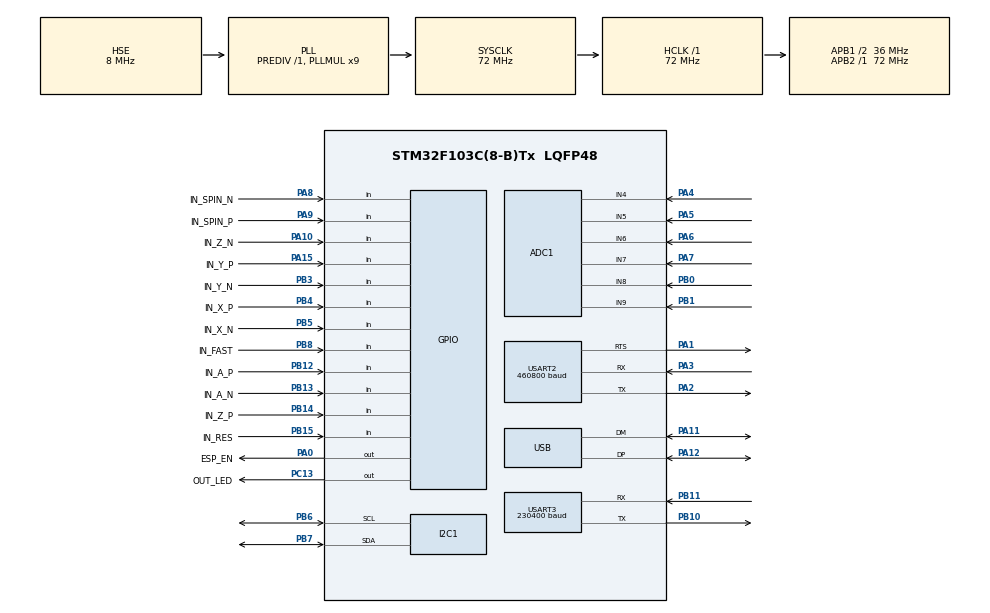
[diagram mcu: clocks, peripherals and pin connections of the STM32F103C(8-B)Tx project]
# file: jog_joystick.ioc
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ADC1.Channel-1\#ChannelRegularConversion=ADC_CHANNEL_4
ADC1.Channel-2\#ChannelRegularConversion=ADC_CHANNEL_5
ADC1.Channel-3\#ChannelRegularConversion=ADC_CHANNEL_6
ADC1.Channel-4\#ChannelRegularConversion=ADC_CHANNEL_7
ADC1.Channel-5\#ChannelRegularConversion=ADC_CHANNEL_8
ADC1.Channel-6\#ChannelRegularConversion=ADC_CHANNEL_9
ADC1.Channel-7\#ChannelRegularConversion=ADC_CHANNEL_VREFINT
ADC1.Channel-8\#ChannelRegularConversion=ADC_CHANNEL_VREFINT
ADC1.ContinuousConvMode=DISABLE
ADC1.ExternalTrigConv=ADC_EXTERNALTRIGCONV_T3_TRGO
ADC1.NbrOfConversion=8
ADC1.NbrOfConversionFlag=1
ADC1.Rank-1\#ChannelRegularConversion=1
ADC1.Rank-2\#ChannelRegularConversion=2
ADC1.Rank-3\#ChannelRegularConversion=3
ADC1.Rank-4\#ChannelRegularConversion=4
ADC1.Rank-5\#ChannelRegularConversion=5
ADC1.Rank-6\#ChannelRegularConversion=6
ADC1.Rank-7\#ChannelRegularConversion=7
ADC1.Rank-8\#ChannelRegularConversion=8
ADC1.SamplingTime-1\#ChannelRegularConversion=ADC_SAMPLETIME_239CYCLES_5
ADC1.SamplingTime-2\#ChannelRegularConversion=ADC_SAMPLETIME_239CYCLES_5
ADC1.SamplingTime-3\#ChannelRegularConversion=ADC_SAMPLETIME_239CYCLES_5
ADC1.SamplingTime-4\#ChannelRegularConversion=ADC_SAMPLETIME_239CYCLES_5
ADC1.SamplingTime-5\#ChannelRegularConversion=ADC_SAMPLETIME_239CYCLES_5
ADC1.SamplingTime-6\#ChannelRegularConversion=ADC_SAMPLETIME_239CYCLES_5
ADC1.SamplingTime-7\#ChannelRegularConversion=ADC_SAMPLETIME_239CYCLES_5
ADC1.SamplingTime-8\#ChannelRegularConversion=ADC_SAMPLETIME_1CYCLE_5
ADC1.master=1
Dma.ADC1.0.Direction=DMA_PERIPH_TO_MEMORY
Dma.ADC1.0.Instance=DMA1_Channel1
Dma.ADC1.0.MemDataAlignment=DMA_MDATAALIGN_HALFWORD
Dma.ADC1.0.MemInc=DMA_MINC_ENABLE
Dma.ADC1.0.Mode=DMA_CIRCULAR
Dma.ADC1.0.PeriphDataAlignment=DMA_PDATAALIGN_HALFWORD
Dma.ADC1.0.PeriphInc=DMA_PINC_DISABLE
Dma.ADC1.0.Priority=DMA_PRIORITY_MEDIUM
Dma.Request0=ADC1
FREERTOS.INCLUDE_pcTaskGetTaskName=0
FREERTOS.INCLUDE_uxTaskGetStackHighWaterMark=0
FREERTOS.INCLUDE_uxTaskPriorityGet=0
FREERTOS.INCLUDE_vTaskDelayUntil=1
FREERTOS.INCLUDE_vTaskDelete=0
FREERTOS.INCLUDE_vTaskPrioritySet=0
FREERTOS.INCLUDE_vTaskSuspend=0
FREERTOS.INCLUDE_xEventGroupSetBitFromISR=0
FREERTOS.INCLUDE_xTaskGetCurrentTaskHandle=0
FREERTOS.INCLUDE_xTaskGetHandle=0
FREERTOS.INCLUDE_xTaskGetSchedulerState=0
FREERTOS.INCLUDE_xTimerPendFunctionCall=0
FREERTOS.MEMORY_ALLOCATION=1
FREERTOS.Tasks01=defaultTask,-1,256,StartDefaultTask,As weak,NULL,Static,defaultTaskBuffer,defaultTaskControlBlock
FREERTOS.configCHECK_FOR_STACK_OVERFLOW=0
FREERTOS.configENABLE_BACKWARD_COMPATIBILITY=0
FREERTOS.configMAX_PRIORITIES=4
FREERTOS.configMINIMAL_STACK_SIZE=128
FREERTOS.configTIMER_QUEUE_LENGTH=8
FREERTOS.configTIMER_TASK_STACK_DEPTH=128
FREERTOS.configTOTAL_HEAP_SIZE=1024
FREERTOS.configUSE_APPLICATION_TASK_TAG=1
FREERTOS.configUSE_NEWLIB_REENTRANT=1
FREERTOS.configUSE_TRACE_FACILITY=0
I2C1.I2C_Mode=I2C_Standard
IWDG.Prescaler=IWDG_PRESCALER_8
Mcu.Family=STM32F1
Mcu.Name=STM32F103C(8-B)Tx
Mcu.Package=LQFP48
NVIC.DMA1_Channel1_IRQn=true\:5\:0\:false\:false\:true\:true\:false\:true\:true
NVIC.I2C1_ER_IRQn=true\:5\:0\:false\:false\:true\:true\:true\:true\:true
NVIC.I2C1_EV_IRQn=true\:5\:0\:false\:false\:true\:true\:true\:true\:true
NVIC.PriorityGroup=NVIC_PRIORITYGROUP_4
NVIC.TIM4_IRQn=true\:15\:0\:false\:false\:true\:false\:false\:true\:true
NVIC.TimeBase=TIM4_IRQn
NVIC.TimeBaseIP=TIM4
NVIC.USART2_IRQn=true\:5\:0\:false\:false\:true\:true\:true\:true\:true
NVIC.USART3_IRQn=true\:5\:0\:false\:false\:true\:true\:true\:true\:true
NVIC.USB_LP_CAN1_RX0_IRQn=true\:5\:0\:false\:false\:true\:true\:false\:true\:true
PA0-WKUP.GPIO_Label=ESP_EN
PA0-WKUP.GPIO_ModeDefaultOutputPP=GPIO_MODE_OUTPUT_OD
PA0-WKUP.GPIO_PuPd=GPIO_NOPULL
PA0-WKUP.Signal=GPIO_Output
PA1.Mode=RTS_Only
PA1.Signal=USART2_RTS
PA10.GPIO_Label=IN_Z_N
PA10.Signal=GPIO_Input
PA11.Mode=Device
PA11.Signal=USB_DM
PA12.Mode=Device
PA12.Signal=USB_DP
PA13.Mode=Serial_Wire
PA13.Signal=SYS_JTMS-SWDIO
PA14.Mode=Serial_Wire
PA14.Signal=SYS_JTCK-SWCLK
PA15.GPIO_Label=IN_Y_P
PA15.Signal=GPIO_Input
PA2.Mode=Asynchronous
PA2.Signal=USART2_TX
PA3.Mode=Asynchronous
PA3.Signal=USART2_RX
PA4.Signal=ADCx_IN4
PA5.Signal=ADCx_IN5
PA6.Signal=ADCx_IN6
PA7.Signal=ADCx_IN7
PA8.GPIO_Label=IN_SPIN_N
PA8.Signal=GPIO_Input
PA9.GPIO_Label=IN_SPIN_P
PA9.Signal=GPIO_Input
PB0.Signal=ADCx_IN8
PB1.Signal=ADCx_IN9
PB10.Mode=Asynchronous
PB10.Signal=USART3_TX
PB11.Mode=Asynchronous
PB11.Signal=USART3_RX
PB12.GPIO_Label=IN_A_P
PB12.Signal=GPIO_Input
PB13.GPIO_Label=IN_A_N
PB13.Signal=GPIO_Input
PB14.GPIO_Label=IN_Z_P
PB14.Signal=GPIO_Input
PB15.GPIO_Label=IN_RES
PB15.Signal=GPIO_Input
PB3.GPIO_Label=IN_Y_N
PB3.Signal=GPIO_Input
PB4.GPIO_Label=IN_X_P
PB4.Signal=GPIO_Input
PB5.GPIO_Label=IN_X_N
PB5.Signal=GPIO_Input
PB6.Mode=I2C
PB6.Signal=I2C1_SCL
PB7.Mode=I2C
PB7.Signal=I2C1_SDA
PB8.GPIO_Label=IN_FAST
PB8.Signal=GPIO_Input
PC13-TAMPER-RTC.GPIO_Label=OUT_LED
PC13-TAMPER-RTC.GPIO_ModeDefaultOutputPP=GPIO_MODE_OUTPUT_OD
PC13-TAMPER-RTC.GPIO_PuPd=GPIO_NOPULL
PC13-TAMPER-RTC.PinState=GPIO_PIN_SET
PC13-TAMPER-RTC.Signal=GPIO_Output
PC14-OSC32_IN.Mode=LSE-External-Oscillator
PC14-OSC32_IN.Signal=RCC_OSC32_IN
PC15-OSC32_OUT.Mode=LSE-External-Oscillator
PC15-OSC32_OUT.Signal=RCC_OSC32_OUT
PD0-OSC_IN.Mode=HSE-External-Oscillator
PD0-OSC_IN.Signal=RCC_OSC_IN
PD1-OSC_OUT.Mode=HSE-External-Oscillator
PD1-OSC_OUT.Signal=RCC_OSC_OUT
ProjectManager.HeapSize=0x200
ProjectManager.StackSize=0x400
ProjectManager.TargetToolchain=Makefile
RCC.ADCPresc=RCC_ADCPCLK2_DIV6
RCC.AHBFreq_Value=72000000
RCC.APB1CLKDivider=RCC_HCLK_DIV2
RCC.APB1Freq_Value=36000000
RCC.APB1TimFreq_Value=72000000
RCC.APB2Freq_Value=72000000
RCC.APB2TimFreq_Value=72000000
RCC.HCLKFreq_Value=72000000
RCC.PLLMUL=RCC_PLL_MUL9
RCC.PLLSourceVirtual=RCC_PLLSOURCE_HSE
RCC.SYSCLKFreq_VALUE=72000000
RCC.SYSCLKSource=RCC_SYSCLKSOURCE_PLLCLK
RCC.USBFreq_Value=48000000
RCC.USBPrescaler=RCC_USBCLKSOURCE_PLL_DIV1_5
SH.ADCx_IN4.0=ADC1_IN4,IN4
SH.ADCx_IN5.0=ADC1_IN5,IN5
SH.ADCx_IN6.0=ADC1_IN6,IN6
SH.ADCx_IN7.0=ADC1_IN7,IN7
SH.ADCx_IN8.0=ADC1_IN8,IN8
SH.ADCx_IN9.0=ADC1_IN9,IN9
TIM2.Prescaler=72-1
TIM3.Period=60000-1
TIM3.Prescaler=12-1
TIM3.TIM_MasterOutputTrigger=TIM_TRGO_UPDATE
USART2.BaudRate=460800
USART2.VirtualMode=VM_ASYNC
USART3.BaudRate=230400
USART3.Parity=PARITY_ODD
USART3.VirtualMode=VM_ASYNC
USART3.WordLength=WORDLENGTH_9B
USB_DEVICE.APP_RX_DATA_SIZE=64
USB_DEVICE.APP_TX_DATA_SIZE=64
USB_DEVICE.CLASS_NAME_FS=CDC
USB_DEVICE.MANUFACTURER_STRING=MDC
USB_DEVICE.PRODUCT_STRING_CDC_FS=CNC Jog Controller
USB_DEVICE.USBD_MAX_STR_DESC_SIZ=64
USB_DEVICE.VirtualMode=Cdc
USB_DEVICE.VirtualModeFS=Cdc_FS
VP_ADC1_Vref_Input.Mode=IN-Vrefint
VP_CRC_VS_CRC.Mode=CRC_Activate
VP_FREERTOS_VS_CMSIS_V1.Mode=CMSIS_V1
VP_IWDG_VS_IWDG.Mode=IWDG_Activate
VP_SYS_VS_tim4.Mode=TIM4
VP_TIM2_VS_ClockSourceINT.Mode=Internal
VP_TIM3_VS_ClockSourceINT.Mode=Internal
VP_USB_DEVICE_VS_USB_DEVICE_CDC_FS.Mode=CDC_FS
board=custom

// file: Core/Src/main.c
/* USER CODE BEGIN Header */
/**
  ******************************************************************************
  * @file           : main.c
  * @brief          : Main program body
  ******************************************************************************
  * @attention
  *
  * Copyright (c) 2024 STMicroelectronics.
  * All rights reserved.
  *
  * This software is licensed under terms that can be found in the LICENSE file
  * in the root directory of this software component.
  * If no LICENSE file comes with this software, it is provided AS-IS.
  *
  ******************************************************************************
  */
/* USER CODE END Header */
#include "main.h"
#include "cmsis_os.h"
#include "adc.h"
#include "crc.h"
#include "dma.h"
#include "i2c.h"
#include "iwdg.h"
#include "tim.h"
#include "usart.h"
#include "usb_device.h"
#include "gpio.h"

/* USER CODE BEGIN Includes */
#include "../User/ushell/inc/sys_command_line.h"
/* USER CODE END Includes */

void SystemClock_Config(void);
void MX_FREERTOS_Init(void);

int main(void)
{

  /* MCU Configuration--------------------------------------------------------*/

  /* Reset of all peripherals, Initializes the Flash interface and the Systick. */
  HAL_Init();

  /* Configure the system clock */
  SystemClock_Config();

  /* Initialize all configured peripherals */
  MX_GPIO_Init();
  MX_DMA_Init();
  MX_ADC1_Init();
  MX_I2C1_Init();
  MX_USART2_UART_Init();
  MX_TIM3_Init();
  MX_IWDG_Init();
  MX_CRC_Init();
  MX_USART3_UART_Init();
  MX_TIM2_Init();

  /* Call init function for freertos objects (in freertos.c) */
  MX_FREERTOS_Init();

  /* Start scheduler */
  osKernelStart();

  /* We should never get here as control is now taken by the scheduler */
  /* Infinite loop */
  while (1)
  {

  }
}

void SystemClock_Config(void)
{
  RCC_OscInitTypeDef RCC_OscInitStruct = {0};
  RCC_ClkInitTypeDef RCC_ClkInitStruct = {0};
  RCC_PeriphCLKInitTypeDef PeriphClkInit = {0};

  /** Initializes the RCC Oscillators according to the specified parameters
  * in the RCC_OscInitTypeDef structure.
  */
  RCC_OscInitStruct.OscillatorType = RCC_OSCILLATORTYPE_LSI|RCC_OSCILLATORTYPE_HSE;
  RCC_OscInitStruct.HSEState = RCC_HSE_ON;
  RCC_OscInitStruct.HSEPredivValue = RCC_HSE_PREDIV_DIV1;
  RCC_OscInitStruct.HSIState = RCC_HSI_ON;
  RCC_OscInitStruct.LSIState = RCC_LSI_ON;
  RCC_OscInitStruct.PLL.PLLState = RCC_PLL_ON;
  RCC_OscInitStruct.PLL.PLLSource = RCC_PLLSOURCE_HSE;
  RCC_OscInitStruct.PLL.PLLMUL = RCC_PLL_MUL9;
  if (HAL_RCC_OscConfig(&RCC_OscInitStruct) != HAL_OK)
  {
    Error_Handler();
  }

  /** Initializes the CPU, AHB and APB buses clocks
  */
  RCC_ClkInitStruct.ClockType = RCC_CLOCKTYPE_HCLK|RCC_CLOCKTYPE_SYSCLK
                              |RCC_CLOCKTYPE_PCLK1|RCC_CLOCKTYPE_PCLK2;
  RCC_ClkInitStruct.SYSCLKSource = RCC_SYSCLKSOURCE_PLLCLK;
  RCC_ClkInitStruct.AHBCLKDivider = RCC_SYSCLK_DIV1;
  RCC_ClkInitStruct.APB1CLKDivider = RCC_HCLK_DIV2;
  RCC_ClkInitStruct.APB2CLKDivider = RCC_HCLK_DIV1;

  if (HAL_RCC_ClockConfig(&RCC_ClkInitStruct, FLASH_LATENCY_2) != HAL_OK)
  {
    Error_Handler();
  }
  PeriphClkInit.PeriphClockSelection = RCC_PERIPHCLK_ADC|RCC_PERIPHCLK_USB;
  PeriphClkInit.AdcClockSelection = RCC_ADCPCLK2_DIV6;
  PeriphClkInit.UsbClockSelection = RCC_USBCLKSOURCE_PLL_DIV1_5;
  if (HAL_RCCEx_PeriphCLKConfig(&PeriphClkInit) != HAL_OK)
  {
    Error_Handler();
  }
}

void HAL_TIM_PeriodElapsedCallback(TIM_HandleTypeDef *htim)
{
  if (htim->Instance == TIM4) {
    HAL_IncTick();
  }
}

void Error_Handler(void)
{
  /* USER CODE BEGIN Error_Handler_Debug */
  DIE("HAL ERROR!");
  /* User can add his own implementation to report the HAL error return state */
  __disable_irq();
  while (1)
  {
  }
  /* USER CODE END Error_Handler_Debug */
}

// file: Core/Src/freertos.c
/* USER CODE BEGIN Header */
/**
  ******************************************************************************
  * File Name          : freertos.c
  * Description        : Code for freertos applications
  ******************************************************************************
  * @attention
  *
  * Copyright (c) 2024 STMicroelectronics.
  * All rights reserved.
  *
  * This software is licensed under terms that can be found in the LICENSE file
  * in the root directory of this software component.
  * If no LICENSE file comes with this software, it is provided AS-IS.
  *
  ******************************************************************************
  */
/* USER CODE END Header */

#include "FreeRTOS.h"
#include "task.h"
#include "main.h"
#include "cmsis_os.h"

/* USER CODE BEGIN Includes */
#include "../User/user.h"
/* USER CODE END Includes */

osThreadId defaultTaskHandle;
uint32_t defaultTaskBuffer[ 256 ];
osStaticThreadDef_t defaultTaskControlBlock;

void StartDefaultTask(void const * argument);

extern void MX_USB_DEVICE_Init(void);
void MX_FREERTOS_Init(void); /* (MISRA C 2004 rule 8.1) */

/* GetIdleTaskMemory prototype (linked to static allocation support) */
void vApplicationGetIdleTaskMemory( StaticTask_t **ppxIdleTaskTCBBuffer, StackType_t **ppxIdleTaskStackBuffer, uint32_t *pulIdleTaskStackSize );

/* GetTimerTaskMemory prototype (linked to static allocation support) */
void vApplicationGetTimerTaskMemory( StaticTask_t **ppxTimerTaskTCBBuffer, StackType_t **ppxTimerTaskStackBuffer, uint32_t *pulTimerTaskStackSize );

/* USER CODE BEGIN GET_IDLE_TASK_MEMORY */
static StaticTask_t xIdleTaskTCBBuffer;
static StackType_t xIdleStack[configMINIMAL_STACK_SIZE];

void vApplicationGetIdleTaskMemory( StaticTask_t **ppxIdleTaskTCBBuffer, StackType_t **ppxIdleTaskStackBuffer, uint32_t *pulIdleTaskStackSize )
{
  *ppxIdleTaskTCBBuffer = &xIdleTaskTCBBuffer;
  *ppxIdleTaskStackBuffer = &xIdleStack[0];
  *pulIdleTaskStackSize = configMINIMAL_STACK_SIZE;
  /* place for user code */
}
/* USER CODE END GET_IDLE_TASK_MEMORY */

/* USER CODE BEGIN GET_TIMER_TASK_MEMORY */
static StaticTask_t xTimerTaskTCBBuffer;
static StackType_t xTimerStack[configTIMER_TASK_STACK_DEPTH];

void vApplicationGetTimerTaskMemory( StaticTask_t **ppxTimerTaskTCBBuffer, StackType_t **ppxTimerTaskStackBuffer, uint32_t *pulTimerTaskStackSize )
{
  *ppxTimerTaskTCBBuffer = &xTimerTaskTCBBuffer;
  *ppxTimerTaskStackBuffer = &xTimerStack[0];
  *pulTimerTaskStackSize = configTIMER_TASK_STACK_DEPTH;
  /* place for user code */
}
/* USER CODE END GET_TIMER_TASK_MEMORY */

void MX_FREERTOS_Init(void) {

  /* Create the thread(s) */
  /* definition and creation of defaultTask */
  osThreadStaticDef(defaultTask, StartDefaultTask, osPriorityBelowNormal, 0, 256, defaultTaskBuffer, &defaultTaskControlBlock);
  defaultTaskHandle = osThreadCreate(osThread(defaultTask), NULL);

}

__weak void StartDefaultTask(void const * argument)
{
  /* init code for USB_DEVICE */
  MX_USB_DEVICE_Init();
  /* USER CODE BEGIN StartDefaultTask */
  /* Infinite loop */
  for(;;)
  {
    osDelay(100);
    HAL_GPIO_TogglePin(OUT_LED_GPIO_Port, OUT_LED_Pin);
  }
  /* USER CODE END StartDefaultTask */
}
